AUTOSAR XML (schema 4-0-3)
standard types defined: Boolean, UInt16, UInt32, UInt8
package /AUTOSAR_Platform/DataConstrs
  range DC_Boolean: raw 0..1
  range DC_UInt16: raw 0..65535
  range DC_UInt8: raw 0..255
package /PATAC/MSM/ComponentTypes
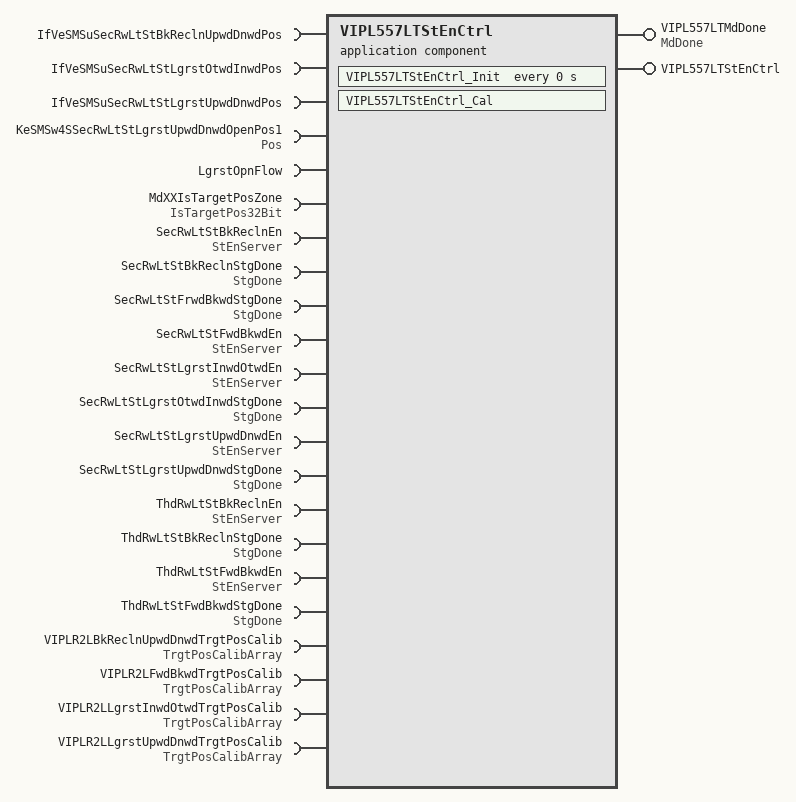
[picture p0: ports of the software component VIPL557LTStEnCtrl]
  application sw component type VIPL557LTStEnCtrl
    provide port VIPL557LTMdDone: nonqueued-sender-com-spec{data-element=MdDone/Val, init-value=0}, provided-interface=MdDone
    provide port VIPL557LTStEnCtrl: server-com-spec{operation=VIPL557LTStEnCtrl/Cal, queue-length=1}, provided-interface=VIPL557LTStEnCtrl
    22 x require port:
      IfVeSMSuSecRwLtStBkReclnUpwdDnwdPos: nonqueued-receiver-com-spec{data-element=IfVeSMSuSecRwLtStBkReclnUpwdDnwdPos/Val, filter=data-filter-type=ALWAYS, init-value=0}, required-interface=IfVeSMSuSecRwLtStBkReclnUpwdDnwdPos
      IfVeSMSuSecRwLtStLgrstOtwdInwdPos: nonqueued-receiver-com-spec{data-element=IfVeSMSuSecRwLtStLgrstOtwdInwdPos/Val, filter=data-filter-type=ALWAYS, init-value=0}, required-interface=IfVeSMSuSecRwLtStLgrstOtwdInwdPos
      IfVeSMSuSecRwLtStLgrstUpwdDnwdPos: nonqueued-receiver-com-spec{data-element=IfVeSMSuSecRwLtStLgrstUpwdDnwdPos/Val, filter=data-filter-type=ALWAYS, init-value=0}, required-interface=IfVeSMSuSecRwLtStLgrstUpwdDnwdPos
      KeSMSw4SSecRwLtStLgrstUpwdDnwdOpenPos1: parameter-require-com-spec{init-value=0, parameter=Val}, required-interface=Pos
      LgrstOpnFlow: client-com-spec=LgrstOpnFlow/Cal, required-interface=LgrstOpnFlow
      MdXXIsTargetPosZone: nonqueued-receiver-com-spec{data-element=IsTargetPos32Bit/Val, filter=data-filter-type=ALWAYS, init-value=0}, required-interface=IsTargetPos32Bit
      SecRwLtStBkReclnEn: required-com-specs=[Clear, Get, Set], required-interface=StEnServer
      SecRwLtStBkReclnStgDone: nonqueued-receiver-com-spec{data-element=StgDone/Val, filter=data-filter-type=ALWAYS, init-value=0}, required-interface=StgDone
      SecRwLtStFrwdBkwdStgDone: nonqueued-receiver-com-spec{data-element=StgDone/Val, filter=data-filter-type=ALWAYS, init-value=0}, required-interface=StgDone
      SecRwLtStFwdBkwdEn: required-com-specs=[Clear, Get, Set], required-interface=StEnServer
      SecRwLtStLgrstInwdOtwdEn: required-com-specs=[Clear, Get, Set], required-interface=StEnServer
      SecRwLtStLgrstOtwdInwdStgDone: nonqueued-receiver-com-spec{data-element=StgDone/Val, filter=data-filter-type=ALWAYS, init-value=0}, required-interface=StgDone
      SecRwLtStLgrstUpwdDnwdEn: required-com-specs=[Clear, Get, Set], required-interface=StEnServer
      SecRwLtStLgrstUpwdDnwdStgDone: nonqueued-receiver-com-spec{data-element=StgDone/Val, filter=data-filter-type=ALWAYS, init-value=0}, required-interface=StgDone
      ThdRwLtStBkReclnEn: required-com-specs=[Clear, Get, Set], required-interface=StEnServer
      ThdRwLtStBkReclnStgDone: nonqueued-receiver-com-spec{data-element=StgDone/Val, filter=data-filter-type=ALWAYS, init-value=0}, required-interface=StgDone
      ThdRwLtStFwdBkwdEn: required-com-specs=[Clear, Get, Set], required-interface=StEnServer
      ThdRwLtStFwdBkwdStgDone: nonqueued-receiver-com-spec{data-element=StgDone/Val, filter=data-filter-type=ALWAYS, init-value=0}, required-interface=StgDone
      VIPLR2LBkReclnUpwdDnwdTrgtPosCalib: nonqueued-receiver-com-spec{data-element=TrgtPosArray, filter=data-filter-type=ALWAYS, init-value=[4095, 4095, 4095]}, required-interface=TrgtPosCalibArray
      VIPLR2LFwdBkwdTrgtPosCalib: nonqueued-receiver-com-spec{data-element=TrgtPosArray, filter=data-filter-type=ALWAYS, init-value=[4095, 4095, 4095]}, required-interface=TrgtPosCalibArray
      VIPLR2LLgrstInwdOtwdTrgtPosCalib: nonqueued-receiver-com-spec{data-element=TrgtPosArray, filter=data-filter-type=ALWAYS, init-value=[4095, 4095, 4095]}, required-interface=TrgtPosCalibArray
      VIPLR2LLgrstUpwdDnwdTrgtPosCalib: nonqueued-receiver-com-spec{data-element=TrgtPosArray, filter=data-filter-type=ALWAYS, init-value=[4095, 4095, 4095]}, required-interface=TrgtPosCalibArray
    behavior VIPL557LTStEnCtrl_InternalBehavior
      operation invoked event OIT_VIPL557LTStEnCtrl_Cal_VIPL557LTStEnCtrl_Cal: start-on-event=VIPL557LTStEnCtrl_Cal, operation=VIPL557LTStEnCtrl.Cal
      timing event VIPL557LTStEnCtrl_InitEvent: start-on-event=VIPL557LTStEnCtrl_Init, period=0
      runnable VIPL557LTStEnCtrl_Cal
        data-receive-point-by-arguments:
          14 x access:
            REC_IfVeSMSuSecRwLtStBkReclnUpwdDnwdPos_Val: accessed-variable=IfVeSMSuSecRwLtStBkReclnUpwdDnwdPos.Val
            REC_IfVeSMSuSecRwLtStLgrstOtwdInwdPos_Val: accessed-variable=IfVeSMSuSecRwLtStLgrstOtwdInwdPos.Val
            REC_IfVeSMSuSecRwLtStLgrstUpwdDnwdPos_Val: accessed-variable=IfVeSMSuSecRwLtStLgrstUpwdDnwdPos.Val
            REC_MdXXIsTargetPosZone_Val: accessed-variable=MdXXIsTargetPosZone.Val
            REC_SecRwLtStBkReclnStgDone_Val: accessed-variable=SecRwLtStBkReclnStgDone.Val
            REC_SecRwLtStFrwdBkwdStgDone_Val: accessed-variable=SecRwLtStFrwdBkwdStgDone.Val
            REC_SecRwLtStLgrstOtwdInwdStgDone_Val: accessed-variable=SecRwLtStLgrstOtwdInwdStgDone.Val
            REC_SecRwLtStLgrstUpwdDnwdStgDone_Val: accessed-variable=SecRwLtStLgrstUpwdDnwdStgDone.Val
            REC_ThdRwLtStBkReclnStgDone_Val: accessed-variable=ThdRwLtStBkReclnStgDone.Val
            REC_ThdRwLtStFwdBkwdStgDone_Val: accessed-variable=ThdRwLtStFwdBkwdStgDone.Val
            REC_VIPLR2LBkReclnUpwdDnwdTrgtPosCalib_TrgtPosArray: accessed-variable=VIPLR2LBkReclnUpwdDnwdTrgtPosCalib.TrgtPosArray
            REC_VIPLR2LFwdBkwdTrgtPosCalib_TrgtPosArray: accessed-variable=VIPLR2LFwdBkwdTrgtPosCalib.TrgtPosArray
            REC_VIPLR2LLgrstInwdOtwdTrgtPosCalib_TrgtPosArray: accessed-variable=VIPLR2LLgrstInwdOtwdTrgtPosCalib.TrgtPosArray
            REC_VIPLR2LLgrstUpwdDnwdTrgtPosCalib_TrgtPosArray: accessed-variable=VIPLR2LLgrstUpwdDnwdTrgtPosCalib.TrgtPosArray
        data-send-points:
          access SEND_VIPLT557MdDone_Val: accessed-variable=VIPL557LTMdDone.Val
        parameter access PA_KeSMSw4SSecRwLtStLgrstUpwdDnwdOpenPos1_Val: accessed-parameter=KeSMSw4SSecRwLtStLgrstUpwdDnwdOpenPos1.Val
        13 x sync call, all with timeout=0:
          SC_LgrstOpnFlow_Cal: operation=LgrstOpnFlow.Cal
          SC_SecRwLtStBkReclnEn_Clear: operation=SecRwLtStBkReclnEn.Clear
          SC_SecRwLtStBkReclnEn_Set: operation=SecRwLtStBkReclnEn.Set
          SC_SecRwLtStFwdBkwdEn_Clear: operation=SecRwLtStFwdBkwdEn.Clear
          SC_SecRwLtStFwdBkwdEn_Set: operation=SecRwLtStFwdBkwdEn.Set
          SC_SecRwLtStLgrstInwdOtwdEn_Clear: operation=SecRwLtStLgrstInwdOtwdEn.Clear
          SC_SecRwLtStLgrstInwdOtwdEn_Set: operation=SecRwLtStLgrstInwdOtwdEn.Set
          SC_SecRwLtStLgrstUpwdDnwdEn_Clear: operation=SecRwLtStLgrstUpwdDnwdEn.Clear
          SC_SecRwLtStLgrstUpwdDnwdEn_Set: operation=SecRwLtStLgrstUpwdDnwdEn.Set
          SC_ThdRwLtStBkReclnEn_Clear: operation=ThdRwLtStBkReclnEn.Clear
          SC_ThdRwLtStBkReclnEn_Set: operation=ThdRwLtStBkReclnEn.Set
          SC_ThdRwLtStFwdBkwdEn_Clear: operation=ThdRwLtStFwdBkwdEn.Clear
          SC_ThdRwLtStFwdBkwdEn_Set: operation=ThdRwLtStFwdBkwdEn.Set
      runnable VIPL557LTStEnCtrl_Init
        parameter access PA_KeSMSw4SSecRwLtStLgrstUpwdDnwdOpenPos1_Val: accessed-parameter=KeSMSw4SSecRwLtStLgrstUpwdDnwdOpenPos1.Val
  swc implementation VIPL557LTStEnCtrl_Implementation: behavior=VIPL557LTStEnCtrl_InternalBehavior
    code-descriptors:
      code Default: artifact-descriptors=autosar-engineering-object={short-label=Default, category=SWSRC}
package /PATAC/MSM/ModeAdjust/CalPortInterface
  parameter interface Pos
    parameter data prototype Val: sw-calibration-access=READ-WRITE, type=UInt16
package /PATAC/MSM/ModeAdjust/DataType
  impl type TrgtPosCalibArray: category=ARRAY, sw-calibration-access=READ-ONLY, type-emitter=RTE  # 0:pos 1:max 2:min
    element Element: array-size=3, array-size-semantics=FIXED-SIZE, implementation-data-type=UInt16, invalid-value=0
package /PATAC/MSM/ModeAdjust/PortInterface
  client server interface LgrstOpnFlow
    operation Cal
      9 x arg, all with server-argument-impl-policy=USE-ARGUMENT-TYPE:
        LgrstUpwdDnwdPos: type=UInt16, direction=IN
        LgrstUpwdDnwdOpenPos1: type=UInt16, direction=IN
        LgrstUpwdStgDone: type=Boolean, direction=IN
        FtrstStgDone: type=Boolean, direction=IN
        LgrstInwdStgDone: type=Boolean, direction=IN
        Failflg: type=Boolean, direction=OUT
        LgrstInwdOtwdEn: type=Boolean, direction=OUT
        LgrstUpwdDnwdEn: type=Boolean, direction=OUT
        FtrstEn: type=Boolean, direction=OUT
  client server interface StEnServer
    operation Clear
      arg data: type=UInt8, direction=IN, server-argument-impl-policy=USE-ARGUMENT-TYPE
    operation Get
      arg data: type=UInt32, direction=OUT, server-argument-impl-policy=USE-ARGUMENT-TYPE
    operation Set
      arg data: type=UInt8, direction=IN, server-argument-impl-policy=USE-ARGUMENT-TYPE
  client server interface VIPL557LTStEnCtrl
    operation Cal
  4 x sender receiver interface:
    IsTargetPos32Bit: invalidation-policy{data-element=IsTargetPos32Bit/Val, handle-invalid=DONT-INVALIDATE}
      data Val: type=UInt32
    MdDone: invalidation-policy{data-element=MdDone/Val, handle-invalid=DONT-INVALIDATE}
      data Val: type=UInt8
    StgDone: invalidation-policy{data-element=StgDone/Val, handle-invalid=DONT-INVALIDATE}
      data Val: type=Boolean
    TrgtPosCalibArray: invalidation-policy{data-element=TrgtPosArray, handle-invalid=DONT-INVALIDATE}
      data TrgtPosArray: type=TrgtPosCalibArray  # 0:Pos 1:Max 2:Min
package /PATAC/MSM/PortInterfaces
  sender receiver interface IfVeSMSuSecRwLtStBkReclnUpwdDnwdPos: invalidation-policy{data-element=IfVeSMSuSecRwLtStBkReclnUpwdDnwdPos/Val, handle-invalid=DONT-INVALIDATE}
    data Val: type=UInt16
  sender receiver interface IfVeSMSuSecRwLtStLgrstOtwdInwdPos: invalidation-policy{data-element=IfVeSMSuSecRwLtStLgrstOtwdInwdPos/Val, handle-invalid=DONT-INVALIDATE}
    data Val: type=UInt16
  sender receiver interface IfVeSMSuSecRwLtStLgrstUpwdDnwdPos: invalidation-policy{data-element=IfVeSMSuSecRwLtStLgrstUpwdDnwdPos/Val, handle-invalid=DONT-INVALIDATE}
    data Val: type=UInt16
